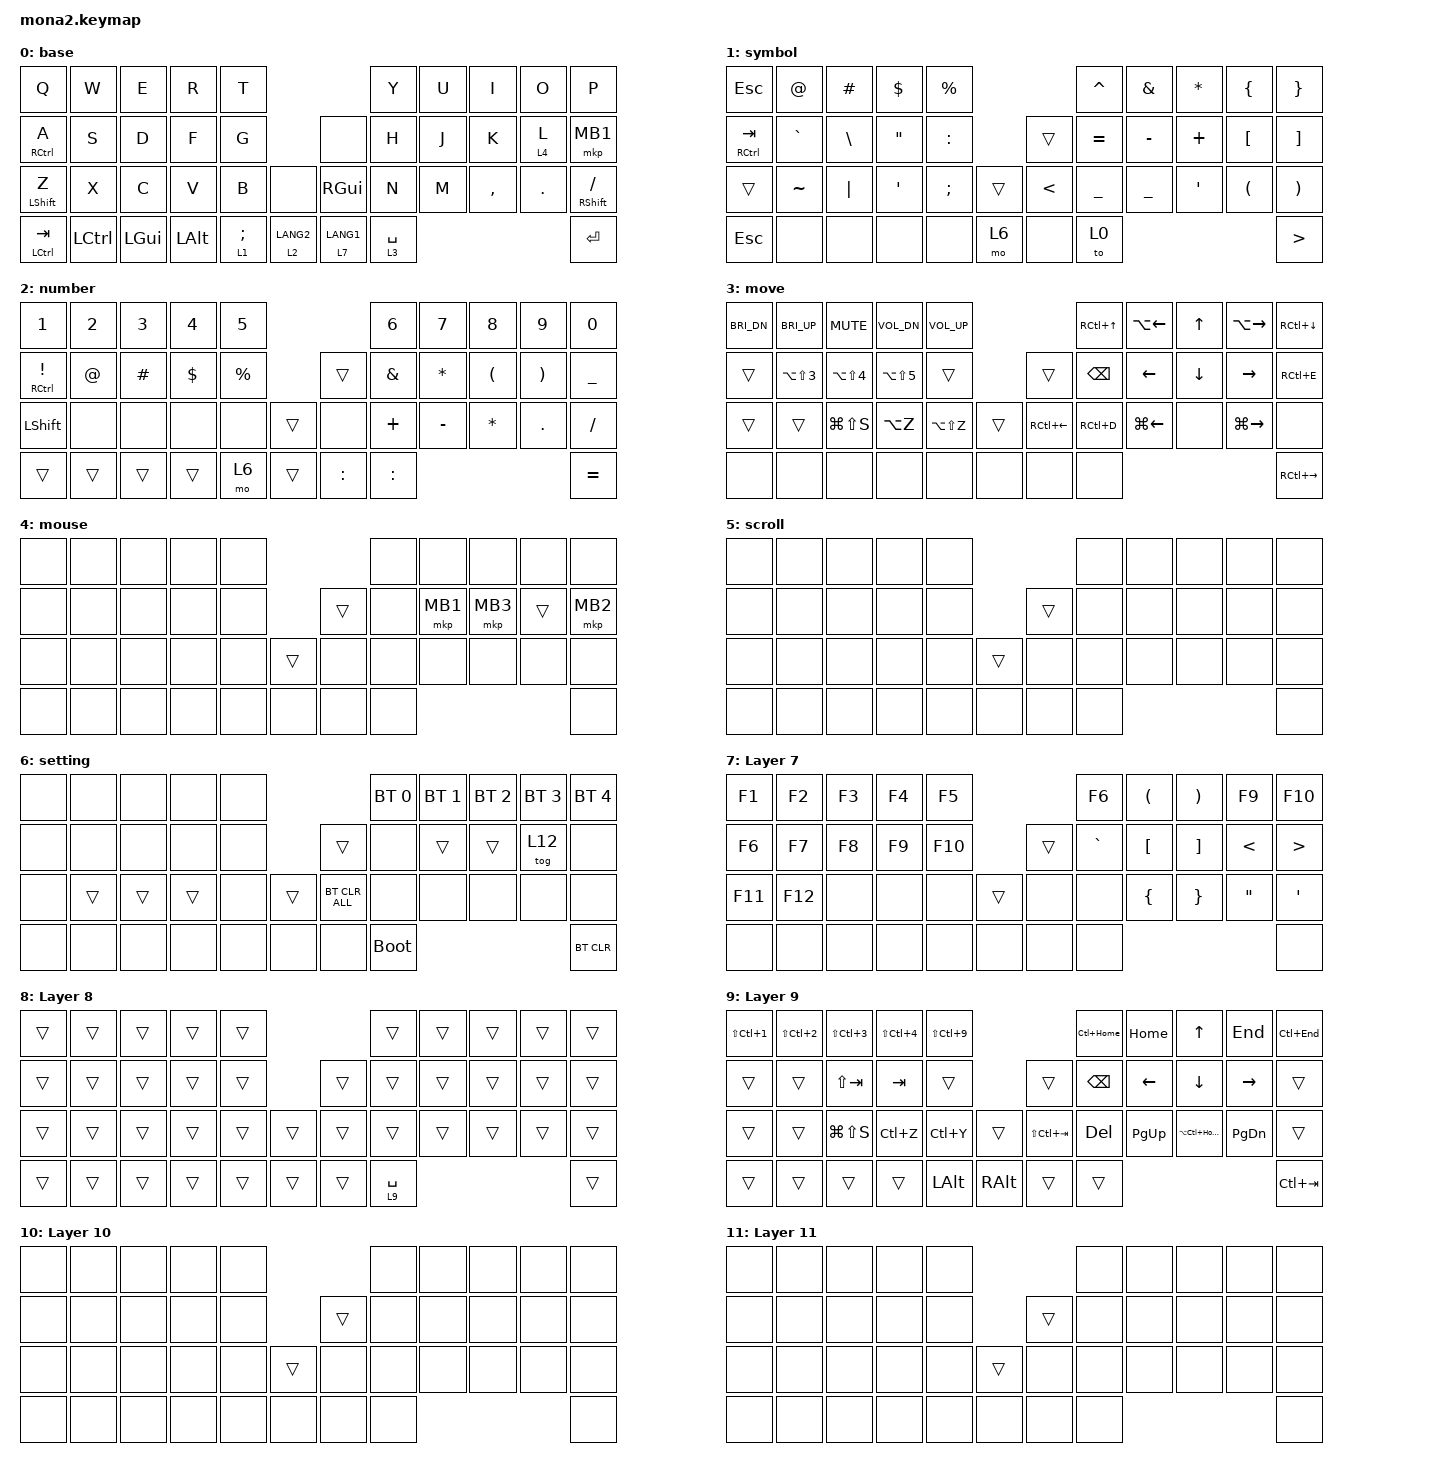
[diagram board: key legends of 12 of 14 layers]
#include <input/processors.dtsi>
#include <dt-bindings/zmk/input_transform.h>
#include <zephyr/dt-bindings/input/input-event-codes.h>
#include <behaviors/runtime-sensor-rotate.dtsi>
#include <behaviors.dtsi>
/* DYA Studio で作ったマクロを `&rmacro <slot>` でキーに置けるようにする（slot 0〜7） */
#include <behaviors/runtime_macro.dtsi>
/* デフォルトレイヤー変更 behavior `&df`（DYA Studio のキーマップエディタで `&df DF_SEL <layer>` などを置ける） */
#include <behaviors/default_layer.dtsi>
#include <dt-bindings/zmk_behavior_default_layer/default_layer.h>
#include <dt-bindings/zmk/bt.h>
#include <dt-bindings/zmk/keys.h>
#include <dt-bindings/zmk/outputs.h>
#include <dt-bindings/zmk/pointing.h>

/*
 * moNa2 × Conductor キーマップ（ベース: shakushakupanda/zmk-config-moNa2-v2 の DYA Studio 版）
 *
 * - レイヤーとコンボは tools/conductor_to_zmk.py が Conductor Studio の JSON から生成する
 *   （下の GENERATED の区間）。キー位置の対応はスクリプトの先頭に書いてある。
 * - upstream の WIN/MAC ペアのレイヤーはやめて、Conductor と同じ 14 枚
 *   （0 base / 1 symbol / 2 number / 3 move / 4 mouse / 5 scroll / 6 setting / 7 F キー /
 *     8 / 9 / 10 / 11 / 12 Precision / 13 Gesture）にした。
 *   接続先 / OS ごとのデフォルトレイヤー機能は残してある（選べる範囲は 0..8。mona2_r.conf 参照）。
 * - 長押しキーは CLine46 で実機確認した 3 種類の自作 hold-tap を使う。
 */

/* エンコーダーのスクロール量（ZMK の既定 10 を上書き） */
#undef ZMK_POINTING_DEFAULT_SCRL_VAL
#define ZMK_POINTING_DEFAULT_SCRL_VAL 100

&msc {
    delay-ms = <0>;
    time-to-max-speed-ms = <0>;
    acceleration-exponent = <0>;
};

/ {
    behaviors {
        /* ===== 長押しキー（CLine46-stable と同じ値） =====
         * Conductor Studio は Mod-Tap / Layer-Tap の判定を別々に調整できないので、用途ごとに分けた。
         *   mt_home  : 文字キーなどの Mod-Tap（Conductor と同じ tap-preferred / 160ms / quick-tap 0）
         *   lt_thumb : 親指の Layer-Tap（balanced / 200ms。tap-preferred だと速打ちで
         *              「親指↓ J↓ J↑ 親指↑」がレイヤーではなく ;j になった＝CLine46 で確認）
         *   lt_mouse : L 長押しでマウスレイヤー（同じ右手でクリックするので tap-preferred）
         */
        mt_home: mt_home {
            compatible = "zmk,behavior-hold-tap";
            display-name = "MT Home";
            #binding-cells = <2>;
            bindings = <&kp>, <&kp>;
            flavor = "tap-preferred";
            tapping-term-ms = <160>;
            quick-tap-ms = <0>;
        };

        lt_thumb: lt_thumb {
            compatible = "zmk,behavior-hold-tap";
            display-name = "LT Thumb";
            #binding-cells = <2>;
            bindings = <&mo>, <&kp>;
            flavor = "balanced";
            tapping-term-ms = <200>;
        };

        lt_mouse: lt_mouse {
            compatible = "zmk,behavior-hold-tap";
            display-name = "LT Mouse";
            #binding-cells = <2>;
            bindings = <&mo>, <&kp>;
            flavor = "tap-preferred";
            tapping-term-ms = <200>;
        };

        /* マウスジェスチャー用キー（upstream から。今はどのキーにも置いていない。DYA Studio から置ける） */
        mg_set_0: behavior_mg_set_0 {
            compatible = "zmk,behavior-mg-set-fixed";
            #binding-cells = <0>;
            display-name = "Mouse Gesture Key 0";
        };
        mg_set_1: behavior_mg_set_1 {
            compatible = "zmk,behavior-mg-set-fixed";
            #binding-cells = <0>;
            display-name = "Mouse Gesture Key 1";
        };
        mg_set_2: behavior_mg_set_2 {
            compatible = "zmk,behavior-mg-set-fixed";
            #binding-cells = <0>;
            display-name = "Mouse Gesture Key 2";
        };

        /* エンコーダー（左手のつまみ）: 回すとスクロール。DYA Studio からレイヤーごとに変えられる */
        rsr_default: rsr_default {
            compatible = "zmk,behavior-runtime-sensor-rotate";
            #sensor-binding-cells = <0>;
            tap-ms = <16>;
            cw-binding = <&msc SCRL_DOWN>;
            ccw-binding = <&msc SCRL_UP>;
        };
    };
};

/* ===== BEGIN GENERATED: conductor_to_zmk.py ===== */
/* 元データ: conductor-keymap2.json（Conductor Monokey / updatedAt 2026-11-16T14:05:48.665Z）。手で直さず、JSON を更新して再生成する */
/ {
    runtime_combo_defaults {
        compatible = "cormoran,runtime-combo-defaults";

        combo_0 {
            slot = <0>;
            display-name = "L7";
            key-positions = <38 39>;
            bindings = <&mo 7>;
            timeout-ms = <100>;
        };

        combo_1 {
            slot = <1>;
            display-name = "MB2";
            key-positions = <19 20>;
            bindings = <&mkp MB2>;
        };

        combo_2 {
            slot = <2>;
            display-name = "MB3";
            key-positions = <18 20>;
            bindings = <&mkp MB3>;
        };

        combo_3 {
            slot = <3>;
            display-name = "L5";
            key-positions = <18 19>;
            bindings = <&mo 5>;
        };

        combo_4 {
            slot = <4>;
            display-name = "L13";
            key-positions = <7 8>;
            bindings = <&mo 13>;
        };

        combo_5 {
            slot = <5>;
            display-name = "Boot";
            key-positions = <8 25 4>;
            bindings = <&bootloader>;
        };
    };

    keymap {
        compatible = "zmk,keymap";

        base {
            display-name = "base";
            bindings = <
&kp Q                 &kp W                 &kp E                 &kp R                 &kp T                                                             &kp Y                 &kp U                 &kp I                 &kp O                 &kp P
&mt_home RCTRL A      &kp S                 &kp D                 &kp F                 &kp G                                       &none                 &kp H                 &kp J                 &kp K                 &lt_mouse 4 L         &mkp MB1
&mt_home LSHIFT Z     &kp X                 &kp C                 &kp V                 &kp B                 &none                 &kp RGUI              &kp N                 &kp M                 &kp COMMA             &kp DOT               &mt_home RSHIFT FSLH
&mt_home LCTRL TAB    &kp LCTRL             &kp LGUI              &kp LALT              &lt_thumb 1 SEMI      &lt_thumb 2 LANG2     &lt_thumb 7 LANG1     &lt_thumb 3 SPACE                                                                       &kp ENTER
            >;
            sensor-bindings = <&rsr_default>, <&inc_dec_kp C_VOL_DN C_VOL_UP>;
        };

        symbol {
            display-name = "symbol";
            bindings = <
&kp ESC             &kp AT              &kp HASH            &kp DLLR            &kp PRCNT                                                   &kp CARET           &kp AMPS            &kp STAR            &kp LBRC            &kp RBRC
&mt_home RCTRL TAB  &kp GRAVE           &kp BSLH            &kp DQT             &kp COLON                               &trans              &kp EQUAL           &kp MINUS           &kp PLUS            &kp LBKT            &kp RBKT
&trans              &kp TILDE           &kp PIPE            &kp SQT             &kp SEMI            &trans              &kp LT              &kp UNDER           &kp UNDER           &kp SQT             &kp LPAR            &kp RPAR
&kp ESC             &none               &none               &none               &none               &mo 6               &none               &to 0                                                                           &kp GT
            >;
            sensor-bindings = <&rsr_default>;
        };

        number {
            display-name = "number";
            bindings = <
&kp N1               &kp N2               &kp N3               &kp N4               &kp N5                                                         &kp N6               &kp N7               &kp N8               &kp N9               &kp N0
&mt_home RCTRL EXCL  &kp AT               &kp HASH             &kp DLLR             &kp PRCNT                                 &trans               &kp AMPS             &kp STAR             &kp LPAR             &kp RPAR             &kp UNDER
&kp LSHIFT           &none                &none                &none                &none                &trans               &none                &kp PLUS             &kp MINUS            &kp STAR             &kp DOT              &kp FSLH
&trans               &trans               &trans               &trans               &mo 6                &trans               &kp COLON            &kp COLON                                                                           &kp EQUAL
            >;
            sensor-bindings = <&rsr_default>;
        };

        move {
            display-name = "move";
            bindings = <
&kp C_BRI_DN    &kp C_BRI_UP    &kp C_MUTE      &kp C_VOL_DN    &kp C_VOL_UP                                    &kp RC(UP)      &kp LA(LEFT)    &kp UP          &kp LA(RIGHT)   &kp RC(DOWN)
&trans          &kp LA(LS(N3))  &kp LA(LS(N4))  &kp LA(LS(N5))  &trans                          &trans          &kp BSPC        &kp LEFT        &kp DOWN        &kp RIGHT       &kp RC(E)
&trans          &trans          &kp LG(LS(S))   &kp LA(Z)       &kp LA(LS(Z))   &trans          &kp RC(LEFT)    &kp RC(D)       &kp LG(LEFT)    &none           &kp LG(RIGHT)   &none
&none           &none           &none           &none           &none           &none           &none           &none                                                           &kp RC(RIGHT)
            >;
            sensor-bindings = <&rsr_default>;
        };

        mouse {
            display-name = "mouse";
            bindings = <
&none     &none     &none     &none     &none                         &none     &none     &none     &none     &none
&none     &none     &none     &none     &none               &trans    &none     &mkp MB1  &mkp MB3  &trans    &mkp MB2
&none     &none     &none     &none     &none     &trans    &none     &none     &none     &none     &none     &none
&none     &none     &none     &none     &none     &none     &none     &none                                   &none
            >;
            sensor-bindings = <&rsr_default>;
        };

        scroll {
            display-name = "scroll";
            bindings = <
&none   &none   &none   &none   &none                   &none   &none   &none   &none   &none
&none   &none   &none   &none   &none           &trans  &none   &none   &none   &none   &none
&none   &none   &none   &none   &none   &trans  &none   &none   &none   &none   &none   &none
&none   &none   &none   &none   &none   &none   &none   &none                           &none
            >;
            sensor-bindings = <&rsr_default>;
        };

        setting {
            display-name = "setting";
            bindings = <
&none           &none           &none           &none           &none                                           &bt BT_SEL 0    &bt BT_SEL 1    &bt BT_SEL 2    &bt BT_SEL 3    &bt BT_SEL 4
&none           &none           &none           &none           &none                           &trans          &none           &trans          &trans          &tog 12         &none
&none           &trans          &trans          &trans          &none           &trans          &bt BT_CLR_ALL  &none           &none           &none           &none           &none
&none           &none           &none           &none           &none           &none           &none           &bootloader                                                     &bt BT_CLR
            >;
            sensor-bindings = <&rsr_default>;
        };

        layer_7 {
            display-name = "Layer 7";
            bindings = <
&kp F1     &kp F2     &kp F3     &kp F4     &kp F5                           &kp F6     &kp LPAR   &kp RPAR   &kp F9     &kp F10
&kp F6     &kp F7     &kp F8     &kp F9     &kp F10               &trans     &kp GRAVE  &kp LBKT   &kp RBKT   &kp LT     &kp GT
&kp F11    &kp F12    &none      &none      &none      &trans     &none      &none      &kp LBRC   &kp RBRC   &kp DQT    &kp SQT
&none      &none      &none      &none      &none      &none      &none      &none                                       &none
            >;
            sensor-bindings = <&rsr_default>;
        };

        layer_8 {
            display-name = "Layer 8";
            bindings = <
&trans             &trans             &trans             &trans             &trans                                                   &trans             &trans             &trans             &trans             &trans
&trans             &trans             &trans             &trans             &trans                                &trans             &trans             &trans             &trans             &trans             &trans
&trans             &trans             &trans             &trans             &trans             &trans             &trans             &trans             &trans             &trans             &trans             &trans
&trans             &trans             &trans             &trans             &trans             &trans             &trans             &lt_thumb 9 SPACE                                                           &trans
            >;
            sensor-bindings = <&rsr_default>;
        };

        layer_9 {
            display-name = "Layer 9";
            bindings = <
&kp LS(LC(N1))    &kp LS(LC(N2))    &kp LS(LC(N3))    &kp LS(LC(N4))    &kp LS(LC(N9))                                        &kp LC(HOME)      &kp HOME          &kp UP            &kp END           &kp LC(END)
&trans            &trans            &kp LS(TAB)       &kp TAB           &trans                              &trans            &kp BSPC          &kp LEFT          &kp DOWN          &kp RIGHT         &trans
&trans            &trans            &kp LG(LS(S))     &kp LC(Z)         &kp LC(Y)         &trans            &kp LS(LC(TAB))   &kp DEL           &kp PG_UP         &kp LA(LC(HOME))  &kp PG_DN         &trans
&trans            &trans            &trans            &trans            &kp LALT          &kp RALT          &trans            &trans                                                                  &kp LC(TAB)
            >;
            sensor-bindings = <&rsr_default>;
        };

        layer_10 {
            display-name = "Layer 10";
            bindings = <
&none   &none   &none   &none   &none                   &none   &none   &none   &none   &none
&none   &none   &none   &none   &none           &trans  &none   &none   &none   &none   &none
&none   &none   &none   &none   &none   &trans  &none   &none   &none   &none   &none   &none
&none   &none   &none   &none   &none   &none   &none   &none                           &none
            >;
            sensor-bindings = <&rsr_default>;
        };

        layer_11 {
            display-name = "Layer 11";
            bindings = <
&none   &none   &none   &none   &none                   &none   &none   &none   &none   &none
&none   &none   &none   &none   &none           &trans  &none   &none   &none   &none   &none
&none   &none   &none   &none   &none   &trans  &none   &none   &none   &none   &none   &none
&none   &none   &none   &none   &none   &none   &none   &none                           &none
            >;
            sensor-bindings = <&rsr_default>;
        };

        precision {
            display-name = "Precision";
            bindings = <
&trans    &trans    &trans    &trans    &trans                        &none     &none     &none     &none     &none
&trans    &trans    &trans    &trans    &trans              &trans    &none     &mkp MB1  &mkp MB1  &mkp MB2  &mkp MB1
&trans    &trans    &trans    &trans    &trans    &trans    &none     &none     &none     &none     &none     &none
&trans    &trans    &trans    &trans    &trans    &trans    &none     &none                                   &tog 12
            >;
            sensor-bindings = <&rsr_default>;
        };

        gesture {
            display-name = "Gesture";
            bindings = <
&none          &none          &none          &none          &none                                        &none          &none          &kp LC(DOWN)   &none          &none
&none          &none          &none          &none          &none                         &trans         &none          &kp LC(RIGHT)  &none          &kp LC(LEFT)   &none
&none          &none          &none          &none          &none          &trans         &none          &none          &none          &kp LC(UP)     &none          &none
&none          &none          &none          &none          &none          &none          &none          &none                                                       &none
            >;
            sensor-bindings = <&rsr_default>;
        };
    };
};
/* ===== END GENERATED: conductor_to_zmk.py ===== */
